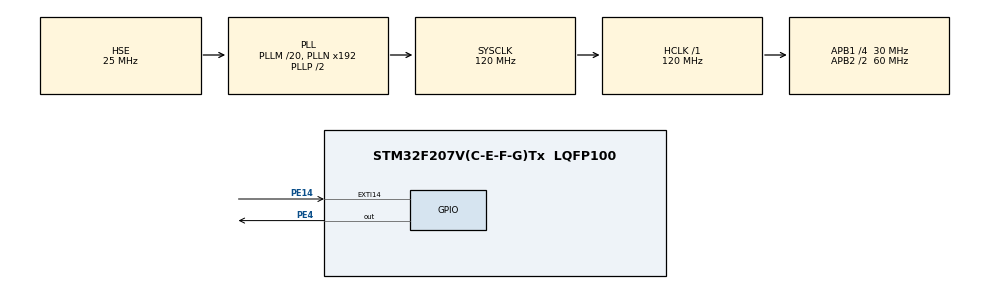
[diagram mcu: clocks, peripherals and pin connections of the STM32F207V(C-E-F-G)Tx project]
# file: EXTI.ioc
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Mcu.Family=STM32F2
Mcu.Name=STM32F207V(C-E-F-G)Tx
Mcu.Package=LQFP100
NVIC.EXTI15_10_IRQn=true\:0\:0\:false\:true\:true\:1\:true\:true
NVIC.PriorityGroup=NVIC_PRIORITYGROUP_4
PA13.Mode=JTAG_4_pins
PA13.Signal=SYS_JTMS-SWDIO
PA14.Mode=JTAG_4_pins
PA14.Signal=SYS_JTCK-SWCLK
PA15.Mode=JTAG_4_pins
PA15.Signal=SYS_JTDI
PB3.Mode=JTAG_4_pins
PB3.Signal=SYS_JTDO-SWO
PE14.GPIO_PuPd=GPIO_PULLUP
PE14.Signal=GPXTI14
PE4.GPIO_PuPd=GPIO_PULLUP
PE4.Signal=GPIO_Output
PH0-OSC_IN.Mode=HSE-External-Oscillator
PH0-OSC_IN.Signal=RCC_OSC_IN
PH1-OSC_OUT.Mode=HSE-External-Oscillator
PH1-OSC_OUT.Signal=RCC_OSC_OUT
ProjectManager.HeapSize=0x200
ProjectManager.StackSize=0x400
ProjectManager.TargetToolchain=EWARM V7
RCC.48MHZClocksFreq_Value=60000000
RCC.AHBFreq_Value=120000000
RCC.APB1CLKDivider=RCC_HCLK_DIV4
RCC.APB1Freq_Value=30000000
RCC.APB1TimFreq_Value=60000000
RCC.APB2CLKDivider=RCC_HCLK_DIV2
RCC.APB2Freq_Value=60000000
RCC.APB2TimFreq_Value=120000000
RCC.CortexFreq_Value=120000000
RCC.HCLKFreq_Value=120000000
RCC.HSE_VALUE=25000000
RCC.HSI_VALUE=16000000
RCC.LSE_VALUE=32768
RCC.PLLM=20
RCC.PLLSourceVirtual=RCC_PLLSOURCE_HSE
RCC.SYSCLKFreq_VALUE=120000000
RCC.SYSCLKSource=RCC_SYSCLKSOURCE_PLLCLK
RCC.VCOOutputFreq_Value=240000000
board=custom

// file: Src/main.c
/* USER CODE BEGIN Header */
/**
  ******************************************************************************
  * @file           : main.c
  * @brief          : Main program body
  ******************************************************************************
  * @attention
  *
  * <h2><center>&copy; Copyright (c) 2021 STMicroelectronics.
  * All rights reserved.</center></h2>
  *
  * This software component is licensed by ST under BSD 3-Clause license,
  * the "License"; You may not use this file except in compliance with the
  * License. You may obtain a copy of the License at:
  *                        opensource.org/licenses/BSD-3-Clause
  *
  ******************************************************************************
  */
/* USER CODE END Header */
#include "main.h"

void SystemClock_Config(void);
static void MX_GPIO_Init(void);
static void MX_NVIC_Init(void);

/* USER CODE BEGIN 0 */
uint8_t flg = 0;
/* USER CODE END 0 */

int main(void)
{

  /* MCU Configuration--------------------------------------------------------*/

  /* Reset of all peripherals, Initializes the Flash interface and the Systick. */
  HAL_Init();

  /* Configure the system clock */
  SystemClock_Config();

  /* Initialize all configured peripherals */
  MX_GPIO_Init();

  /* Initialize interrupts */
  MX_NVIC_Init();

  /* Infinite loop */
  /* USER CODE BEGIN WHILE */
  while (1)
  {
		if(flg == 1)
		{
			flg = 0;
			HAL_GPIO_TogglePin(GPIOE,GPIO_PIN_4);
		}
    /* USER CODE END WHILE */

  }
}

void SystemClock_Config(void)
{
  RCC_OscInitTypeDef RCC_OscInitStruct = {0};
  RCC_ClkInitTypeDef RCC_ClkInitStruct = {0};

  /** Initializes the RCC Oscillators according to the specified parameters
  * in the RCC_OscInitTypeDef structure.
  */
  RCC_OscInitStruct.OscillatorType = RCC_OSCILLATORTYPE_HSE;
  RCC_OscInitStruct.HSEState = RCC_HSE_ON;
  RCC_OscInitStruct.PLL.PLLState = RCC_PLL_ON;
  RCC_OscInitStruct.PLL.PLLSource = RCC_PLLSOURCE_HSE;
  RCC_OscInitStruct.PLL.PLLM = 20;
  RCC_OscInitStruct.PLL.PLLN = 192;
  RCC_OscInitStruct.PLL.PLLP = RCC_PLLP_DIV2;
  RCC_OscInitStruct.PLL.PLLQ = 4;
  if (HAL_RCC_OscConfig(&RCC_OscInitStruct) != HAL_OK)
  {
    Error_Handler();
  }
  /** Initializes the CPU, AHB and APB buses clocks
  */
  RCC_ClkInitStruct.ClockType = RCC_CLOCKTYPE_HCLK|RCC_CLOCKTYPE_SYSCLK
                              |RCC_CLOCKTYPE_PCLK1|RCC_CLOCKTYPE_PCLK2;
  RCC_ClkInitStruct.SYSCLKSource = RCC_SYSCLKSOURCE_PLLCLK;
  RCC_ClkInitStruct.AHBCLKDivider = RCC_SYSCLK_DIV1;
  RCC_ClkInitStruct.APB1CLKDivider = RCC_HCLK_DIV4;
  RCC_ClkInitStruct.APB2CLKDivider = RCC_HCLK_DIV2;

  if (HAL_RCC_ClockConfig(&RCC_ClkInitStruct, FLASH_LATENCY_3) != HAL_OK)
  {
    Error_Handler();
  }
}

/**
  * @brief NVIC Configuration.
  * @retval None
  */
static void MX_NVIC_Init(void)
{
  /* EXTI15_10_IRQn interrupt configuration */
  HAL_NVIC_SetPriority(EXTI15_10_IRQn, 0, 0);
  HAL_NVIC_EnableIRQ(EXTI15_10_IRQn);
}

static void MX_GPIO_Init(void)
{
  GPIO_InitTypeDef GPIO_InitStruct = {0};

  /* GPIO Ports Clock Enable */
  __HAL_RCC_GPIOE_CLK_ENABLE();
  __HAL_RCC_GPIOH_CLK_ENABLE();
  __HAL_RCC_GPIOA_CLK_ENABLE();
  __HAL_RCC_GPIOB_CLK_ENABLE();

  /*Configure GPIO pin Output Level */
  HAL_GPIO_WritePin(GPIOE, GPIO_PIN_4, GPIO_PIN_RESET);

  /*Configure GPIO pin : PE4 */
  GPIO_InitStruct.Pin = GPIO_PIN_4;
  GPIO_InitStruct.Mode = GPIO_MODE_OUTPUT_PP;
  GPIO_InitStruct.Pull = GPIO_PULLUP;
  GPIO_InitStruct.Speed = GPIO_SPEED_FREQ_LOW;
  HAL_GPIO_Init(GPIOE, &GPIO_InitStruct);

  /*Configure GPIO pin : PE14 */
  GPIO_InitStruct.Pin = GPIO_PIN_14;
  GPIO_InitStruct.Mode = GPIO_MODE_IT_RISING;
  GPIO_InitStruct.Pull = GPIO_PULLUP;
  HAL_GPIO_Init(GPIOE, &GPIO_InitStruct);

}

/* USER CODE BEGIN 4 */
void HAL_GPIO_EXTI_Callback(uint16_t GPIO_Pin)
{
	if(GPIO_Pin == GPIO_PIN_14)
	{
		flg = 1;
	}
}
/* USER CODE END 4 */

void Error_Handler(void)
{
  __disable_irq();
  while (1)
  {
  }
}

/************************ (C) COPYRIGHT STMicroelectronics *****END OF FILE****/
